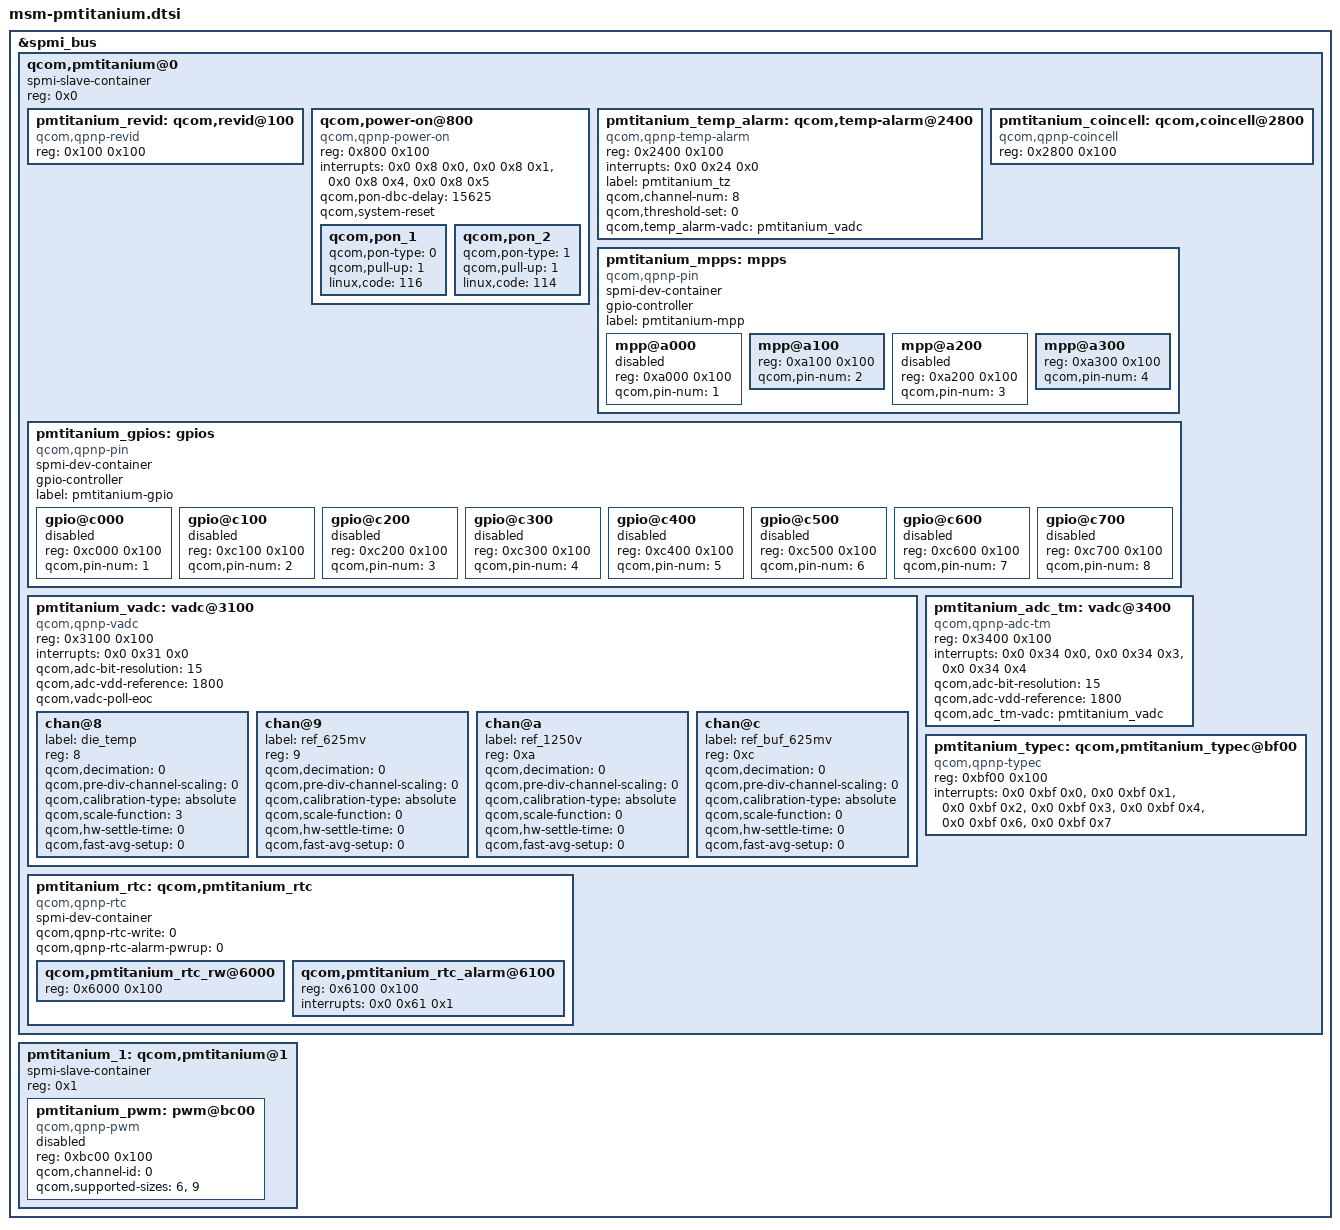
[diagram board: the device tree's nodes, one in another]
/*
 * Copyright (c) 2015, The Linux Foundation. All rights reserved.
 *
 * This program is free software; you can redistribute it and/or modify
 * it under the terms of the GNU General Public License version 2 and
 * only version 2 as published by the Free Software Foundation.
 *
 * This program is distributed in the hope that it will be useful,
 * but WITHOUT ANY WARRANTY; without even the implied warranty of
 * MERCHANTABILITY or FITNESS FOR A PARTICULAR PURPOSE.  See the
 * GNU General Public License for more details.
 */

&spmi_bus {

	qcom,pmtitanium@0 {
		spmi-slave-container;
		reg = <0x0>;
		#address-cells = <1>;
		#size-cells = <1>;

		pmtitanium_revid: qcom,revid@100 {
			compatible = "qcom,qpnp-revid";
			reg = <0x100 0x100>;
		};

		qcom,power-on@800 {
			compatible = "qcom,qpnp-power-on";
			reg = <0x800 0x100>;
			interrupts = <0x0 0x8 0x0>,
				<0x0 0x8 0x1>,
				<0x0 0x8 0x4>,
				<0x0 0x8 0x5>;
			interrupt-names = "kpdpwr", "resin",
				"resin-bark", "kpdpwr-resin-bark";
			qcom,pon-dbc-delay = <15625>;
			qcom,system-reset;

			qcom,pon_1 {
				qcom,pon-type = <0>;
				qcom,pull-up = <1>;
				linux,code = <116>;
			};

			qcom,pon_2 {
				qcom,pon-type = <1>;
				qcom,pull-up = <1>;
				linux,code = <114>;
			};
		};

		pmtitanium_temp_alarm: qcom,temp-alarm@2400 {
			compatible = "qcom,qpnp-temp-alarm";
			reg = <0x2400 0x100>;
			interrupts = <0x0 0x24 0x0>;
			label = "pmtitanium_tz";
			qcom,channel-num = <8>;
			qcom,threshold-set = <0>;
			qcom,temp_alarm-vadc = <&pmtitanium_vadc>;
		};

		pmtitanium_coincell: qcom,coincell@2800 {
			compatible = "qcom,qpnp-coincell";
			reg = <0x2800 0x100>;
		};

		pmtitanium_mpps: mpps {
			compatible = "qcom,qpnp-pin";
			spmi-dev-container;
			gpio-controller;
			#gpio-cells = <2>;
			#address-cells = <1>;
			#size-cells = <1>;
			label = "pmtitanium-mpp";

			mpp@a000 {
				reg = <0xa000 0x100>;
				qcom,pin-num = <1>;
				status = "disabled";
			};

			mpp@a100 {
				reg = <0xa100 0x100>;
				qcom,pin-num = <2>;
			};

			mpp@a200 {
				reg = <0xa200 0x100>;
				qcom,pin-num = <3>;
				status = "disabled";
			};

			mpp@a300 {
				reg = <0xa300 0x100>;
				qcom,pin-num = <4>;
			};
		};

		pmtitanium_gpios: gpios {
			spmi-dev-container;
			compatible = "qcom,qpnp-pin";
			gpio-controller;
			#gpio-cells = <2>;
			#address-cells = <1>;
			#size-cells = <1>;
			label = "pmtitanium-gpio";

			gpio@c000 {
				reg = <0xc000 0x100>;
				qcom,pin-num = <1>;
				status = "disabled";
			};

			gpio@c100 {
				reg = <0xc100 0x100>;
				qcom,pin-num = <2>;
				status = "disabled";
			};

			gpio@c200 {
				reg = <0xc200 0x100>;
				qcom,pin-num = <3>;
				status = "disabled";
			};

			gpio@c300 {
				reg = <0xc300 0x100>;
				qcom,pin-num = <4>;
				status = "disabled";
			};

			gpio@c400 {
				reg = <0xc400 0x100>;
				qcom,pin-num = <5>;
				status = "disabled";
			};

			gpio@c500 {
				reg = <0xc500 0x100>;
				qcom,pin-num = <6>;
				status = "disabled";
			};

			gpio@c600 {
				reg = <0xc600 0x100>;
				qcom,pin-num = <7>;
				status = "disabled";
			};

			gpio@c700 {
				reg = <0xc700 0x100>;
				qcom,pin-num = <8>;
				status = "disabled";
			};
		};

		pmtitanium_vadc: vadc@3100 {
			compatible = "qcom,qpnp-vadc";
			reg = <0x3100 0x100>;
			#address-cells = <1>;
			#size-cells = <0>;
			interrupts = <0x0 0x31 0x0>;
			interrupt-names = "eoc-int-en-set";
			qcom,adc-bit-resolution = <15>;
			qcom,adc-vdd-reference = <1800>;
			qcom,vadc-poll-eoc;

			chan@8 {
				label = "die_temp";
				reg = <8>;
				qcom,decimation = <0>;
				qcom,pre-div-channel-scaling = <0>;
				qcom,calibration-type = "absolute";
				qcom,scale-function = <3>;
				qcom,hw-settle-time = <0>;
				qcom,fast-avg-setup = <0>;
			};

			chan@9 {
				label = "ref_625mv";
				reg = <9>;
				qcom,decimation = <0>;
				qcom,pre-div-channel-scaling = <0>;
				qcom,calibration-type = "absolute";
				qcom,scale-function = <0>;
				qcom,hw-settle-time = <0>;
				qcom,fast-avg-setup = <0>;
			};

			chan@a {
				label = "ref_1250v";
				reg = <0xa>;
				qcom,decimation = <0>;
				qcom,pre-div-channel-scaling = <0>;
				qcom,calibration-type = "absolute";
				qcom,scale-function = <0>;
				qcom,hw-settle-time = <0>;
				qcom,fast-avg-setup = <0>;
			};

			chan@c {
				label = "ref_buf_625mv";
				reg = <0xc>;
				qcom,decimation = <0>;
				qcom,pre-div-channel-scaling = <0>;
				qcom,calibration-type = "absolute";
				qcom,scale-function = <0>;
				qcom,hw-settle-time = <0>;
				qcom,fast-avg-setup = <0>;
			};
		};

		pmtitanium_adc_tm: vadc@3400 {
			compatible = "qcom,qpnp-adc-tm";
			reg = <0x3400 0x100>;
			#address-cells = <1>;
			#size-cells = <0>;
			interrupts =	<0x0 0x34 0x0>,
					<0x0 0x34 0x3>,
					<0x0 0x34 0x4>;
			interrupt-names =	"eoc-int-en-set",
						"high-thr-en-set",
						"low-thr-en-set";
			qcom,adc-bit-resolution = <15>;
			qcom,adc-vdd-reference = <1800>;
			qcom,adc_tm-vadc = <&pmtitanium_vadc>;

		};

		pmtitanium_rtc: qcom,pmtitanium_rtc {
			spmi-dev-container;
			compatible = "qcom,qpnp-rtc";
			#address-cells = <1>;
			#size-cells = <1>;
			qcom,qpnp-rtc-write = <0>;
			qcom,qpnp-rtc-alarm-pwrup = <0>;

			qcom,pmtitanium_rtc_rw@6000 {
				reg = <0x6000 0x100>;
			};

			qcom,pmtitanium_rtc_alarm@6100 {
				reg = <0x6100 0x100>;
				interrupts = <0x0 0x61 0x1>;
			};
		};

		pmtitanium_typec: qcom,pmtitanium_typec@bf00 {
			compatible = "qcom,qpnp-typec";
			reg = <0xbf00 0x100>;
			interrupts =    <0x0 0xbf 0x0>,
					<0x0 0xbf 0x1>,
					<0x0 0xbf 0x2>,
					<0x0 0xbf 0x3>,
					<0x0 0xbf 0x4>,
					<0x0 0xbf 0x6>,
					<0x0 0xbf 0x7>;

			interrupt-names =       "vrd-change",
						"ufp-detect",
						"ufp-detach",
						"dfp-detect",
						"dfp-detach",
						"vbus-err",
						"vconn-oc";
		};
	};

	pmtitanium_1: qcom,pmtitanium@1 {
		spmi-slave-container;
		reg = <0x1>;
		#address-cells = <1>;
		#size-cells = <1>;

		pmtitanium_pwm: pwm@bc00 {
			status = "disabled";
			compatible = "qcom,qpnp-pwm";
			reg = <0xbc00 0x100>;
			reg-names = "qpnp-lpg-channel-base";
			qcom,channel-id = <0>;
			qcom,supported-sizes = <6>, <9>;
			#pwm-cells = <2>;
		};
	};
};
